# STM32WBA24 register map
File version: 0.2
CPU: CM33 r0p1, little endian, MPU, FPU, 4 interrupt priority bits
Registers are 32-bit, read-write, reset 0x0 unless marked. A register's access mark holds for its fields unless they carry their own. Offsets are from the block's base; [hi:lo] are bit positions; {n}, {i} and the like mark numbered series.

## GPIOA — GPIOA address block description
Base 0x42020000
Same registers: SEC_GPIOA 0x52020000
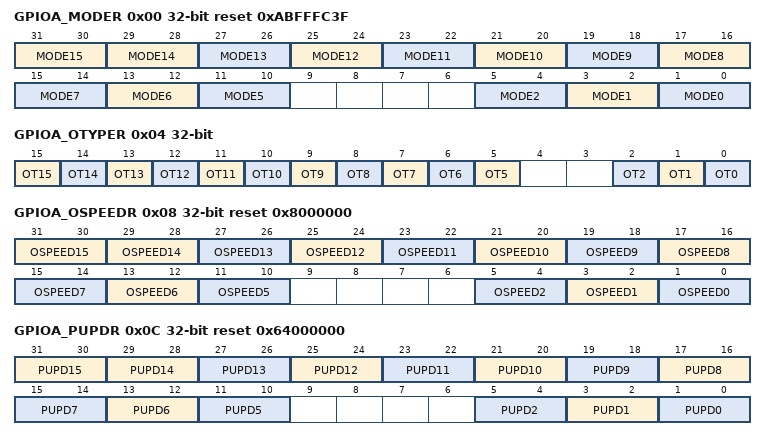
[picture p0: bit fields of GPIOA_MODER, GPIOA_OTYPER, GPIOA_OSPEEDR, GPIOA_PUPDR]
0x00 GPIOA_MODER reset 0xABFFFC3F — GPIO port A mode register
  [31:30] MODE15 — Port configuration I/O pin 15
    0=Input mode; 1=General purpose output mode; 2=Alternate function mode; 3=Analog mode (reset state)
  [2n+1:2n] MODE{n} (n=5..14) — Port configuration I/O pin {n}
  [5:4] MODE2 — Port configuration I/O pin 2
  [3:2] MODE1 — Port configuration I/O pin 1
  [1:0] MODE0 — Port configuration I/O pin 0
0x04 GPIOA_OTYPER — GPIO port A output type register
  [n] OT{n} (n=5..15) — Port configuration I/O pin y
    0=Output push-pull (reset state); 1=Output open-drain
  [2] OT2 — Port configuration I/O pin y
  [1] OT1 — Port configuration I/O pin y
  [0] OT0 — Port configuration I/O pin y
0x08 GPIOA_OSPEEDR reset 0x8000000 — GPIO port A output speed register
  [31:30] OSPEED15 — Port configuration I/O pin 15
    0=Low speed; 1=Medium speed; 2=High speed
  [2n+1:2n] OSPEED{n} (n=5..14) — Port configuration I/O pin {n}
  [5:4] OSPEED2 — Port configuration I/O pin 2
  [3:2] OSPEED1 — Port configuration I/O pin 1
  [1:0] OSPEED0 — Port configuration I/O pin 0
0x0C GPIOA_PUPDR reset 0x64000000 — GPIO port A pull-up/pull-down register
  [31:30] PUPD15 — Port configuration I/O pin 15
    0=No pull-up, pull-down; 1=Pull-up; 2=Pull-down
  [2n+1:2n] PUPD{n} (n=5..14) — Port configuration I/O pin {n}
  [5:4] PUPD2 — Port configuration I/O pin 2
  [3:2] PUPD1 — Port configuration I/O pin 1
  [1:0] PUPD0 — Port configuration I/O pin 0
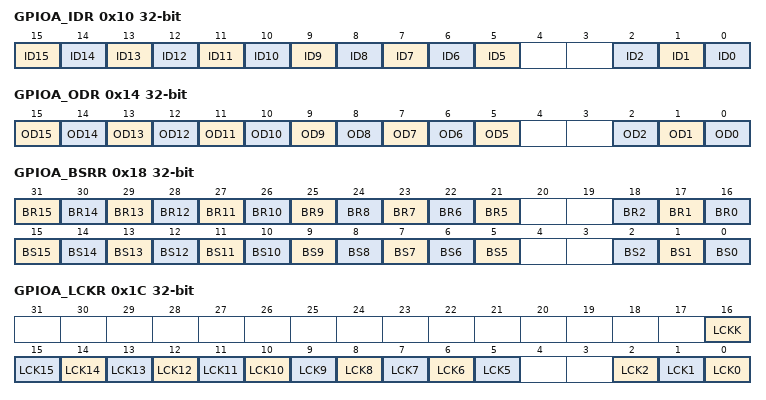
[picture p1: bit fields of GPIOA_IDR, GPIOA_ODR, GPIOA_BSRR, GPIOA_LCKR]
0x10 GPIOA_IDR ro (reset mask 0xFFFF0000) — GPIO port A input data register
  [n] ID{n} (n=5..15) — Port input data I/O pin y
  [2] ID2 — Port input data I/O pin y
  [1] ID1 — Port input data I/O pin y
  [0] ID0 — Port input data I/O pin y
0x14 GPIOA_ODR — GPIO port A output data register
  [n] OD{n} (n=5..15) — Port output data I/O pin y
  [2] OD2 — Port output data I/O pin y
  [1] OD1 — Port output data I/O pin y
  [0] OD0 — Port output data I/O pin y
0x18 GPIOA_BSRR wo — GPIO port A bit set/reset register
  [n+16] BR{n} (n=5..15) — Port reset I/O pin y
    0=No action on the corresponding ODy bit; 1=Resets the corresponding ODy bit
  [18] BR2 — Port reset I/O pin y
  [17] BR1 — Port reset I/O pin y
  [16] BR0 — Port reset I/O pin y
  [n] BS{n} (n=5..15) — Port set I/O pin y
    0=No action on the corresponding ODy bit; 1=Sets the corresponding ODy bit
  [2] BS2 — Port set I/O pin y
  [1] BS1 — Port set I/O pin y
  [0] BS0 — Port set I/O pin y
0x1C GPIOA_LCKR — GPIO port A configuration lock register
  [16] LCKK — Lock key
    0=Port configuration lock key not active; 1=Port configuration lock key active
  [n] LCK{n} (n=5..15) — Port lock I/O pin y
    0=Port configuration not locked; 1=Port configuration locked
  [2] LCK2 — Port lock I/O pin y
  [1] LCK1 — Port lock I/O pin y
  [0] LCK0 — Port lock I/O pin y
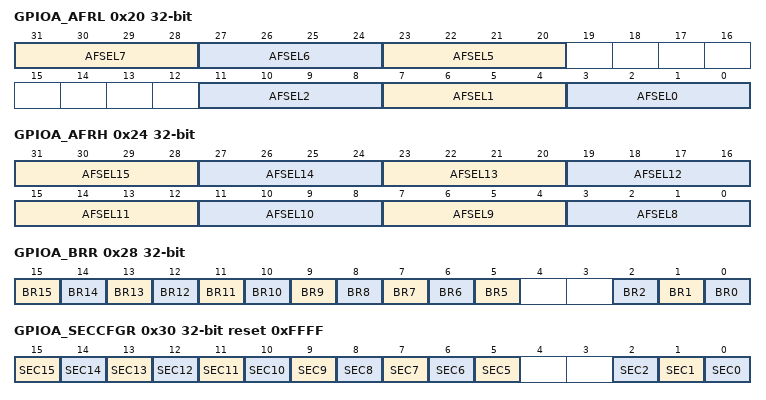
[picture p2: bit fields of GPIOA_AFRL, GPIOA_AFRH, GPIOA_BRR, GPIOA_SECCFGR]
0x20 GPIOA_AFRL — GPIO port A alternate function low register
  [31:28] AFSEL7 — Alternate function selection for port I/O pin 7
    {v}=AF{v} (v=0..15)
  [27:24] AFSEL6 — Alternate function selection for port I/O pin 6
  [23:20] AFSEL5 — Alternate function selection for port I/O pin 5
  [11:8] AFSEL2 — Alternate function selection for port I/O pin 2
  [7:4] AFSEL1 — Alternate function selection for port I/O pin 1
  [3:0] AFSEL0 — Alternate function selection for port I/O pin 0
0x24 GPIOA_AFRH — GPIO port A alternate function high register
  [31:28] AFSEL15 — Alternate function selection for port I/O pin 15
    {v}=AF{v} (v=0..15)
  [4n-29:4n-32] AFSEL{n} (n=8..14) — Alternate function selection for port I/O pin {n}
0x28 GPIOA_BRR wo — GPIO port A bit reset register
  [n] BR{n} (n=5..15) — Port reset I/O pin y
    0=No action on the corresponding ODy bit; 1=Reset the corresponding ODy bit
  [2] BR2 — Port reset I/O pin y
  [1] BR1 — Port reset I/O pin y
  [0] BR0 — Port reset I/O pin y
0x30 GPIOA_SECCFGR wo reset 0xFFFF — GPIO port A secure configuration register
  [all] fields
    0=The I/O pin is non-secure; 1=The I/O pin is secure
  [n] SEC{n} (n=5..15) — I/O pin of port secure bit enable y
  [2] SEC2 — I/O pin of port secure bit enable y
  [1] SEC1 — I/O pin of port secure bit enable y
  [0] SEC0 — I/O pin of port secure bit enable y
